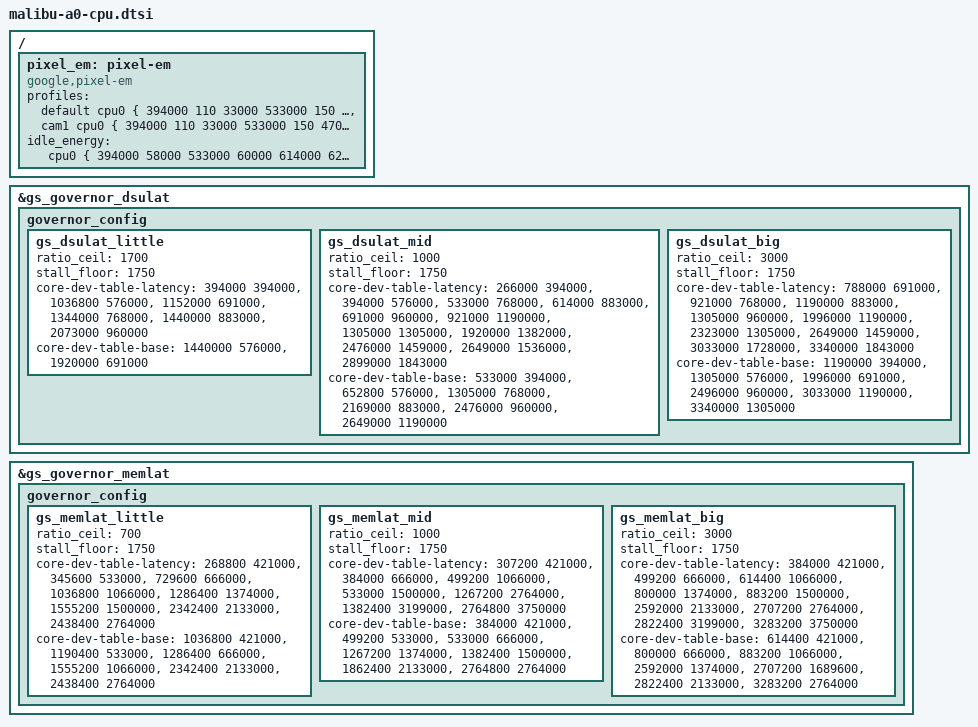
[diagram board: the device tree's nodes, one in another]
// SPDX-License-Identifier: GPL-2.0 OR BSD-3-Clause

&gs_governor_dsulat {
	governor_config {
		gs_dsulat_little {
			ratio_ceil = <1700>;
			stall_floor = <1750>;
			core-dev-table-latency =
			/* Little CPU    DSU */
			<  394000	394000 >,
			< 1036800	576000 >,
			< 1152000	691000 >,
			< 1344000	768000 >,
			< 1440000	883000 >,
			< 2073000	960000 >;

			core-dev-table-base =
			/* Little CPU    DSU */
			< 1440000	576000 >,
			< 1920000	691000 >;
		};
		gs_dsulat_mid {
			ratio_ceil = <1000>;
			stall_floor = <1750>;
			core-dev-table-latency =
			/* Mid CPU       DSU */
			<  266000	 394000 >,
			<  394000	 576000 >,
			<  533000	 768000 >,
			<  614000	 883000 >,
			<  691000	 960000 >,
			<  921000	1190000 >,
			< 1305000	1305000 >,
			< 1920000	1382000 >,
			< 2476000	1459000 >,
			< 2649000	1536000 >,
			< 2899000	1843000 >;

			core-dev-table-base =
			/* Mid CPU       DSU */
			<  533000	 394000 >,
			<  652800	 576000 >,
			< 1305000	 768000 >,
			< 2169000	 883000 >,
			< 2476000	 960000 >,
			< 2649000	1190000 >;

		};
		gs_dsulat_big {
			ratio_ceil = <3000>;
			stall_floor = <1750>;
			core-dev-table-latency =
			/* Big CPU       DSU */
			<  788000	 691000 >,
			<  921000	 768000 >,
			< 1190000	 883000 >,
			< 1305000	 960000 >,
			< 1996000	1190000 >,
			< 2323000	1305000 >,
			< 2649000	1459000 >,
			< 3033000	1728000 >,
			< 3340000	1843000 >;

			core-dev-table-base =
			/* Big CPU       DSU */
			< 1190000	 394000 >,
			< 1305000	 576000 >,
			< 1996000	 691000 >,
			< 2496000	 960000 >,
			< 3033000	1190000 >,
			< 3340000	1305000 >;
		};
	};
};

&gs_governor_memlat {
	governor_config {
		gs_memlat_little {
			ratio_ceil = <700>;
			stall_floor = <1750>;
			core-dev-table-latency =
			/* LITTLE CPU	 GMC */
			<  268800	 421000 >,
			<  345600	 533000 >,
			<  729600	 666000 >,
			< 1036800	1066000 >,
			< 1286400	1374000 >,
			< 1555200	1500000 >,
			< 2342400	2133000 >,
			< 2438400	2764000 >;

			core-dev-table-base =
			/* LITTLE CPU    GMC */
			< 1036800	 421000 >,
			< 1190400	 533000 >,
			< 1286400	 666000 >,
			< 1555200	1066000 >,
			< 2342400	2133000 >,
			< 2438400	2764000 >;
		};
		gs_memlat_mid {
			ratio_ceil = <1000>;
			stall_floor = <1750>;
			core-dev-table-latency =
			/* MID CPU	 GMC */
			<  307200	 421000 >,
			<  384000	 666000 >,
			<  499200	1066000 >,
			<  533000	1500000 >,
			< 1267200	2764000 >,
			< 1382400	3199000 >,
			< 2764800	3750000 >;

			core-dev-table-base =
			/* MID CPU    	 GMC */
			<  384000	 421000 >,
			<  499200	 533000 >,
			<  533000	 666000 >,
			< 1267200	1374000 >,
			< 1382400	1500000 >,
			< 1862400	2133000 >,
			< 2764800	2764000 >;

		};
		gs_memlat_big {
			ratio_ceil = <3000>;
			stall_floor = <1750>;
			core-dev-table-latency =
			/* BIG CPU    	 GMC */
			<  384000	 421000 >,
			<  499200	 666000 >,
			<  614400	1066000 >,
			<  800000	1374000 >,
			<  883200	1500000 >,
			< 2592000	2133000 >,
			< 2707200	2764000 >,
			< 2822400	3199000 >,
			< 3283200	3750000 >;

			core-dev-table-base =
			/* BIG CPU    	GMC */
			<  614400	 421000 >,
			<  800000	 666000 >,
			<  883200	1066000 >,
			< 2592000	1374000 >,
			< 2707200	1689600 >,
			< 2822400	2133000 >,
			< 3283200	2764000 >;
		};
	};
};

/ {
	pixel_em: pixel-em {
		compatible = "google,pixel-em";
		profiles =
			"default
				cpu0 {
				394000 110 33000
				533000 150 47000
				614000 171 56000
				691000 192 65000
				787000 219 77000
				883000 246 90000
				960000 267 100000
				1036000 289 109000
				1152000 322 132000
				1248000 350 151000
				1344000 378 173000
				1440000 405 197000
				1536000 432 221000
				1632000 459 257000
				1728000 486 288000
				1824000 514 325000
				1920000 541 376000
				2073000 584 440000
				2150000 606 476000
				2227000 627 530000
				2342000 660 593000
				2496000 703 720000
				2649000 746 841000
				}
				cpu2 {
				266000 75 24000
				394000 110 37000
				533000 150 54000
				614000 173 64000
				691000 194 73000
				768000 216 86000
				844000 237 98000
				921000 259 110000
				1036000 291 132000
				1171000 329 152000
				1305000 367 180000
				1440000 405 208000
				1574000 443 238000
				1689000 476 275000
				1804000 508 315000
				1920000 541 351000
				2035000 573 402000
				2169000 611 471000
				2304000 649 541000
				2476000 698 648000
				2649000 746 758000
				2899000 817 990000
				3148000 887 991000
				3379000 952 992000
				}
				cpu6 {
				788000 263 349000
				921000 328 465000
				1056000 365 556000
				1190000 432 647000
				1305000 474 714000
				1420000 480 768000
				1555000 535 888000
				1689000 603 1034000
				1843000 623 1152000
				1996000 668 1291000
				2150000 757 1525000
				2323000 829 1715000
				2496000 865 1969000
				2649000 936 2200000
				2803000 984 2342000
				3033000 1001 2884000
				3340000 1022 3615000
				3571000 1023 3616000
				3782000 1024 3617000
				}
			",
			"cam1
				cpu0 {
				394000 110 33000
				533000 150 47000
				614000 111 56000
				691000 124 65000
				787000 142 77000
				883000 159 90000
				960000 173 100000
				1036000 186 109000
				1152000 207 132000
				1248000 225 151000
				1344000 242 173000
				1440000 259 197000
				1536000 276 221000
				1632000 294 257000
				1728000 311 288000
				1824000 328 325000
				1920000 346 376000
				2073000 373 440000
				2150000 387 476000
				2227000 401 530000
				2342000 422 593000
				2496000 449 720000
				2649000 795 1641000
				}
				cpu2 {
				266000 75 24000
				394000 110 37000
				533000 150 54000
				614000 111 64000
				691000 124 73000
				768000 138 86000
				844000 152 98000
				921000 166 110000
				1036000 186 132000
				1171000 211 152000
				1305000 235 180000
				1440000 259 208000
				1574000 283 238000
				1689000 304 275000
				1804000 325 315000
				1920000 346 351000
				2035000 366 402000
				2169000 390 471000
				2304000 415 541000
				2476000 446 648000
				2649000 477 758000
				2899000 522 990000
				3148000 567 1121000
				3379000 1014 2192000
				}
				cpu6 {
				788000 263 379000
				921000 281 465000
				1056000 322 556000
				1190000 363 647000
				1305000 398 714000
				1420000 433 792000
				1555000 474 888000
				1689000 515 1034000
				1843000 562 1152000
				1996000 609 1291000
				2150000 656 1525000
				2323000 709 1715000
				2496000 761 1969000
				2649000 808 2200000
				2803000 855 2342000
				3033000 925 2884000
				3340000 1019 3615000
				3571000 1023 3659000
				3782000 1024 3719000
				}
			";
			idle_energy =
			"
				cpu0 {
				394000 58000
				533000 60000
				614000 62000
				691000 69000
				787000 82000
				883000 92000
				960000 101000
				1036000 111000
				1152000 123000
				1248000 130000
				1344000 150000
				1440000 170000
				1536000 173000
				1632000 200000
				1728000 221000
				1824000 256000
				1920000 273000
				2073000 292000
				2150000 305000
				2227000 362000
				2342000 414000
				2496000 979000
				2649000 1098000
				}
				cpu2 {
				266000 30000
				394000 39000
				533000 48000
				614000 64000
				691000 102000
				768000 111000
				844000 130000
				921000 149000
				1036000 177000
				1171000 200000
				1305000 229000
				1440000 259000
				1574000 286000
				1689000 320000
				1804000 342000
				1920000 404000
				2035000 442000
				2169000 488000
				2304000 527000
				2476000 609000
				2649000 732000
				2899000 876000
				3148000 979000
				3379000 1098000
				}
				cpu6 {
				788000 144000
				921000 192000
				1056000 306000
				1190000 333000
				1305000 390000
				1420000 447000
				1555000 531000
				1689000 600000
				1843000 687000
				1996000 777000
				2150000 858000
				2323000 960000
				2496000 1026000
				2649000 1212000
				2803000 1326000
				3033000 1464000
				3340000 1581000
				3571000 1827000
				3782000 2196000
				}
			";
	};
};
